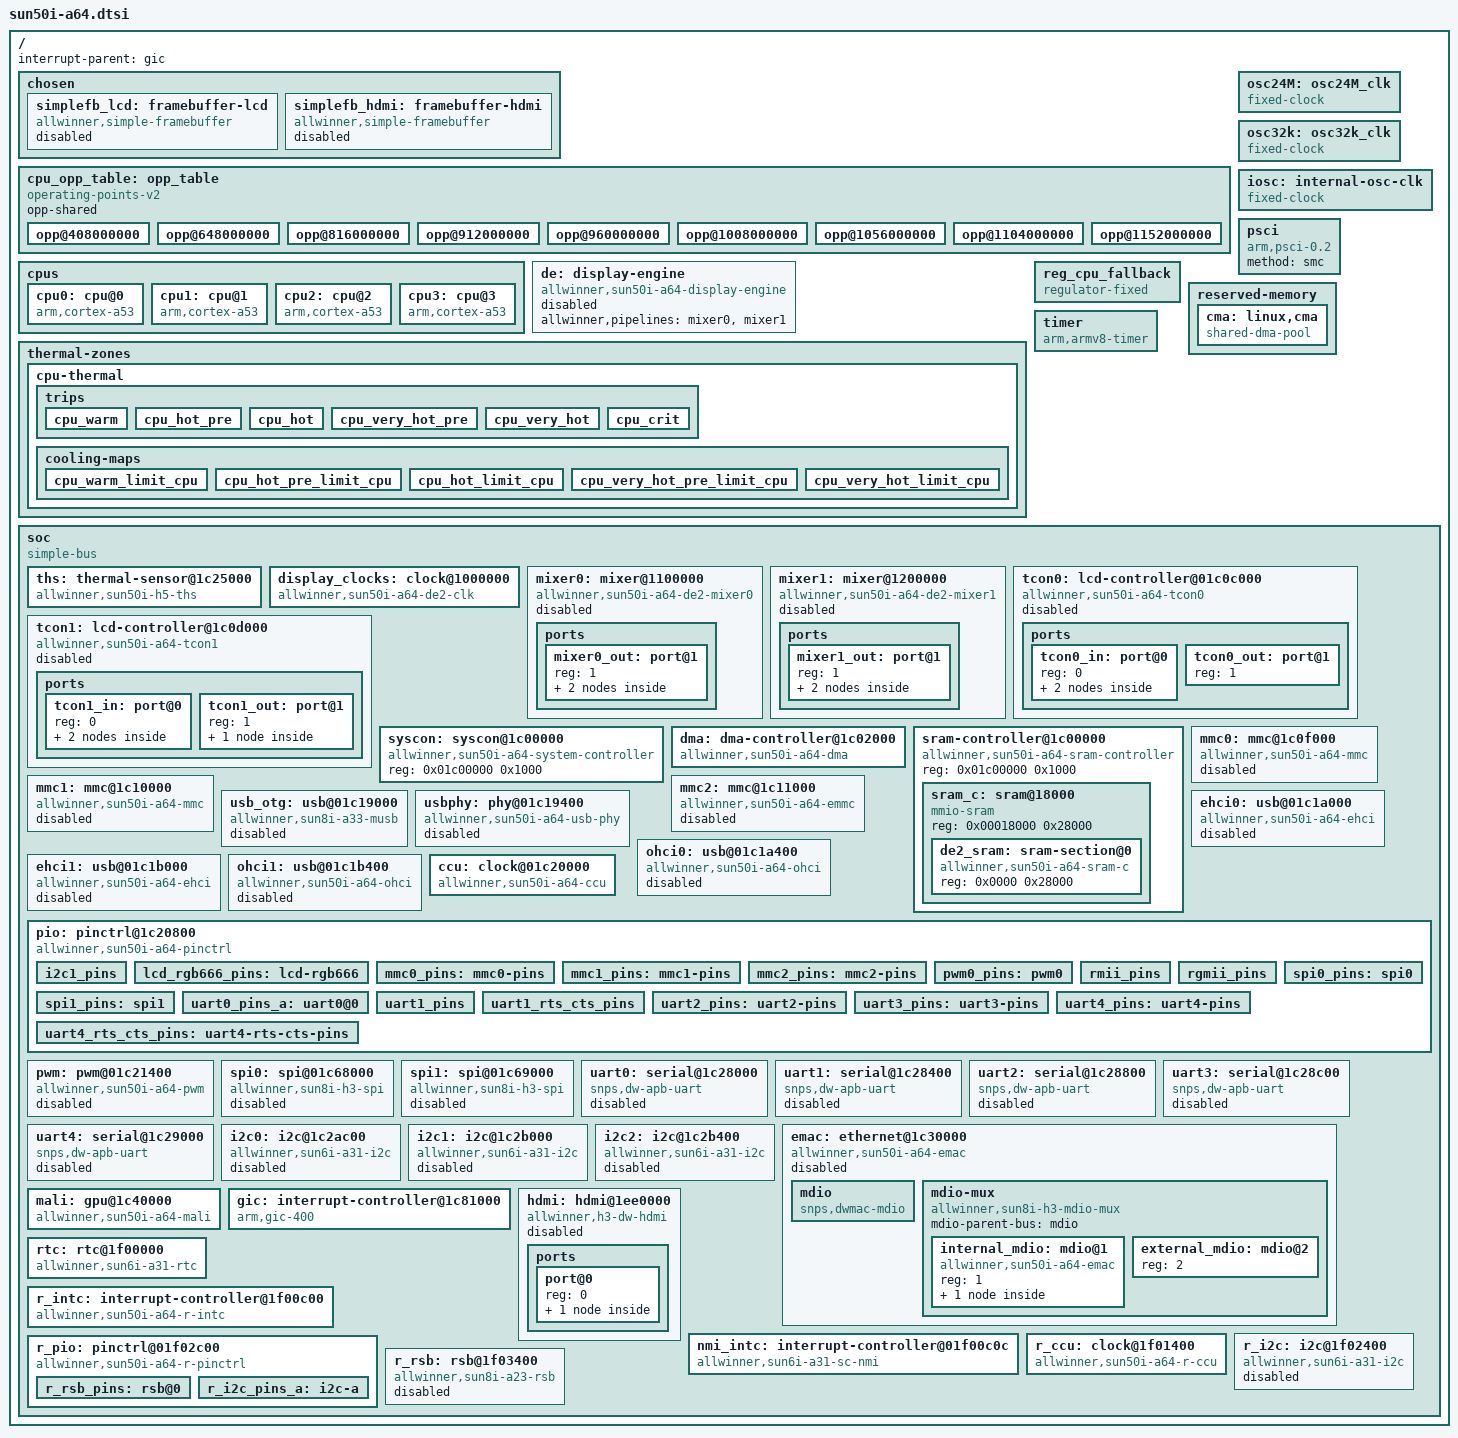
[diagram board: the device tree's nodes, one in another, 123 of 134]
/*
 * Copyright (C) 2016 ARM Ltd.
 * based on the Allwinner H3 dtsi:
 *    Copyright (C) 2015 Jens Kuske <jenskuske@gmail.com>
 *
 * This file is dual-licensed: you can use it either under the terms
 * of the GPL or the X11 license, at your option. Note that this dual
 * licensing only applies to this file, and not this project as a
 * whole.
 *
 *  a) This file is free software; you can redistribute it and/or
 *     modify it under the terms of the GNU General Public License as
 *     published by the Free Software Foundation; either version 2 of the
 *     License, or (at your option) any later version.
 *
 *     This file is distributed in the hope that it will be useful,
 *     but WITHOUT ANY WARRANTY; without even the implied warranty of
 *     MERCHANTABILITY or FITNESS FOR A PARTICULAR PURPOSE.  See the
 *     GNU General Public License for more details.
 *
 * Or, alternatively,
 *
 *  b) Permission is hereby granted, free of charge, to any person
 *     obtaining a copy of this software and associated documentation
 *     files (the "Software"), to deal in the Software without
 *     restriction, including without limitation the rights to use,
 *     copy, modify, merge, publish, distribute, sublicense, and/or
 *     sell copies of the Software, and to permit persons to whom the
 *     Software is furnished to do so, subject to the following
 *     conditions:
 *
 *     The above copyright notice and this permission notice shall be
 *     included in all copies or substantial portions of the Software.
 *
 *     THE SOFTWARE IS PROVIDED "AS IS", WITHOUT WARRANTY OF ANY KIND,
 *     EXPRESS OR IMPLIED, INCLUDING BUT NOT LIMITED TO THE WARRANTIES
 *     OF MERCHANTABILITY, FITNESS FOR A PARTICULAR PURPOSE AND
 *     NONINFRINGEMENT. IN NO EVENT SHALL THE AUTHORS OR COPYRIGHT
 *     HOLDERS BE LIABLE FOR ANY CLAIM, DAMAGES OR OTHER LIABILITY,
 *     WHETHER IN AN ACTION OF CONTRACT, TORT OR OTHERWISE, ARISING
 *     FROM, OUT OF OR IN CONNECTION WITH THE SOFTWARE OR THE USE OR
 *     OTHER DEALINGS IN THE SOFTWARE.
 */

#include <dt-bindings/clock/sun8i-de2.h>
#include <dt-bindings/clock/sun50i-a64-ccu.h>
#include <dt-bindings/clock/sun8i-r-ccu.h>
#include <dt-bindings/interrupt-controller/arm-gic.h>
#include <dt-bindings/reset/sun8i-de2.h>
#include <dt-bindings/reset/sun50i-a64-ccu.h>
#include <dt-bindings/clock/sun8i-de2.h>
#include <dt-bindings/reset/sun8i-de2.h>
#include <dt-bindings/clock/sun8i-r-ccu.h>
#include <dt-bindings/reset/sun8i-r-ccu.h>
#include <dt-bindings/thermal/thermal.h>

/ {
	interrupt-parent = <&gic>;
	#address-cells = <1>;
	#size-cells = <1>;

	chosen {
		#address-cells = <1>;
		#size-cells = <1>;
		ranges;

		simplefb_lcd: framebuffer-lcd {
			compatible = "allwinner,simple-framebuffer",
				     "simple-framebuffer";
			allwinner,pipeline = "mixer0-lcd0";
			clocks = <&display_clocks CLK_BUS_MIXER0>,
				 <&ccu CLK_BUS_TCON0>, <&ccu CLK_BUS_TCON0>,
				 <&display_clocks CLK_MIXER0>,
				 <&ccu CLK_TCON0>;
			status = "disabled";
		};

		simplefb_hdmi: framebuffer-hdmi {
			compatible = "allwinner,simple-framebuffer",
				     "simple-framebuffer";
			allwinner,pipeline = "mixer1-lcd1-hdmi";
			clocks = <&display_clocks CLK_BUS_MIXER1>,
				 <&ccu CLK_BUS_TCON1>, <&ccu CLK_BUS_HDMI>,
				 <&display_clocks CLK_MIXER1>,
				 <&ccu CLK_TCON1>, <&ccu CLK_HDMI>,
				 <&ccu CLK_HDMI_DDC>;
			status = "disabled";
		};
	};

	cpu_opp_table: opp_table {
		compatible = "operating-points-v2";
		opp-shared;

		opp@408000000 {
			opp-hz = /bits/ 64 <408000000>;
			opp-microvolt = <1000000 1000000 1300000>;
			clock-latency-ns = <244144>; /* 8 32k periods */
		};

		opp@648000000 {
			opp-hz = /bits/ 64 <648000000>;
			opp-microvolt = <1040000 1040000 1300000>;
			clock-latency-ns = <244144>; /* 8 32k periods */
		};

		opp@816000000 {
			opp-hz = /bits/ 64 <816000000>;
			opp-microvolt = <1080000 1080000 1300000>;
			clock-latency-ns = <244144>; /* 8 32k periods */
		};

		opp@912000000 {
		       opp-hz = /bits/ 64 <912000000>;
		       opp-microvolt = <1120000 1120000 1300000>;
		       clock-latency-ns = <244144>; /* 8 32k periods */
		};

		opp@960000000 {
		       opp-hz = /bits/ 64 <960000000>;
		       opp-microvolt = <1160000 1160000 1300000>;
		       clock-latency-ns = <244144>; /* 8 32k periods */
		};

		opp@1008000000 {
		       opp-hz = /bits/ 64 <1008000000>;
		       opp-microvolt = <1200000 1200000 1300000>;
		       clock-latency-ns = <244144>; /* 8 32k periods */
		};

		opp@1056000000 {
		       opp-hz = /bits/ 64 <1056000000>;
		       opp-microvolt = <1240000 1240000 1300000>;
		       clock-latency-ns = <244144>; /* 8 32k periods */
		};

		opp@1104000000 {
		       opp-hz = /bits/ 64 <1104000000>;
		       opp-microvolt = <1260000 1260000 1300000>;
		       clock-latency-ns = <244144>; /* 8 32k periods */
		};

		opp@1152000000 {
		       opp-hz = /bits/ 64 <1152000000>;
		       opp-microvolt = <1300000 1300000 1300000>;
		       clock-latency-ns = <244144>; /* 8 32k periods */
		};
	};

	cpus {
		#address-cells = <1>;
		#size-cells = <0>;

		cpu0: cpu@0 {
			compatible = "arm,cortex-a53", "arm,armv8";
			device_type = "cpu";
			reg = <0>;
			enable-method = "psci";
			operating-points-v2 = <&cpu_opp_table>;
			cpu-supply = <&reg_cpu_fallback>;
			#cooling-cells = <2>;
		};

		cpu1: cpu@1 {
			compatible = "arm,cortex-a53", "arm,armv8";
			device_type = "cpu";
			reg = <1>;
			enable-method = "psci";
			operating-points-v2 = <&cpu_opp_table>;
		};

		cpu2: cpu@2 {
			compatible = "arm,cortex-a53", "arm,armv8";
			device_type = "cpu";
			reg = <2>;
			enable-method = "psci";
			operating-points-v2 = <&cpu_opp_table>;
		};

		cpu3: cpu@3 {
			compatible = "arm,cortex-a53", "arm,armv8";
			device_type = "cpu";
			reg = <3>;
			enable-method = "psci";
			operating-points-v2 = <&cpu_opp_table>;
		};
	};

	de: display-engine {
		compatible = "allwinner,sun50i-a64-display-engine";
		allwinner,pipelines = <&mixer0>,
				      <&mixer1>;
		status = "disabled";
	};

	osc24M: osc24M_clk {
		#clock-cells = <0>;
		compatible = "fixed-clock";
		clock-frequency = <24000000>;
		clock-output-names = "osc24M";
	};

	osc32k: osc32k_clk {
		#clock-cells = <0>;
		compatible = "fixed-clock";
		clock-frequency = <32768>;
		clock-output-names = "osc32k";
	};

	iosc: internal-osc-clk {
		#clock-cells = <0>;
		compatible = "fixed-clock";
		clock-frequency = <16000000>;
		clock-accuracy = <300000000>;
		clock-output-names = "iosc";
	};

	psci {
		compatible = "arm,psci-0.2";
		method = "smc";
	};

	thermal-zones {
		cpu-thermal {
			/* milliseconds */
			polling-delay-passive = <250>;
			polling-delay = <1000>;
			thermal-sensors = <&ths>;

			trips {
				cpu_warm: cpu_warm {
					temperature = <65000>;
					hysteresis = <2000>;
					type = "passive";
				};

				cpu_hot_pre: cpu_hot_pre {
					temperature = <70000>;
					hysteresis = <2000>;
					type = "passive";
				};

				cpu_hot: cpu_hot {
					temperature = <75000>;
					hysteresis = <2000>;
					type = "passive";
				};

				cpu_very_hot_pre: cpu_very_hot_pre {
					temperature = <85000>;
					hysteresis = <2000>;
					type = "passive";
				};

				cpu_very_hot: cpu_very_hot {
					temperature = <90000>;
					hysteresis = <2000>;
					type = "passive";
				};

				cpu_crit: cpu_crit {
					temperature = <105000>;
					hysteresis = <2000>;
					type = "critical";
				};
			};

			cooling-maps {
				cpu_warm_limit_cpu {
					trip = <&cpu_warm>;
					cooling-device = <&cpu0 THERMAL_NO_LIMIT 2>;
				};

				cpu_hot_pre_limit_cpu {
					trip = <&cpu_hot_pre>;
					cooling-device = <&cpu0 2 3>;
				};

				cpu_hot_limit_cpu {
					trip = <&cpu_hot>;
					cooling-device = <&cpu0 3 4>;
				};

				cpu_very_hot_pre_limit_cpu {
					trip = <&cpu_very_hot>;
					cooling-device = <&cpu0 5 6>;
				};

				cpu_very_hot_limit_cpu {
					trip = <&cpu_very_hot>;
					cooling-device = <&cpu0 7 THERMAL_NO_LIMIT>;
				};
			};
		};
	};

	reg_cpu_fallback: reg_cpu_fallback  {
		compatible = "regulator-fixed";
		regulator-name = "vdd-cpux-dummy";
		regulator-min-microvolt = <1100000>;
		regulator-max-microvolt = <1100000>;
	};

	reserved-memory {
		#address-cells = <1>;
		#size-cells = <1>;
		ranges;

		cma: linux,cma {
			compatible = "shared-dma-pool";
			reusable;
			size = <0x4000000>;
			alignment = <0x2000>;
			linux,cma-default;
		};
	};
	timer {
		compatible = "arm,armv8-timer";
		fsl,erratum-a008585;
		interrupts = <GIC_PPI 13
			(GIC_CPU_MASK_SIMPLE(4) | IRQ_TYPE_LEVEL_HIGH)>,
			     <GIC_PPI 14
			(GIC_CPU_MASK_SIMPLE(4) | IRQ_TYPE_LEVEL_HIGH)>,
			     <GIC_PPI 11
			(GIC_CPU_MASK_SIMPLE(4) | IRQ_TYPE_LEVEL_HIGH)>,
			     <GIC_PPI 10
			(GIC_CPU_MASK_SIMPLE(4) | IRQ_TYPE_LEVEL_HIGH)>;
	};

	soc {
		compatible = "simple-bus";
		#address-cells = <1>;
		#size-cells = <1>;
		ranges;

		ths: thermal-sensor@1c25000 {
			compatible = "allwinner,sun50i-h5-ths";
			reg = <0x01c25000 0x100>;
			clocks = <&ccu CLK_BUS_THS>, <&ccu CLK_THS>;
			clock-names = "bus", "mod";
			resets = <&ccu RST_BUS_THS>;
			#thermal-sensor-cells = <0>;
			#io-channel-cells = <0>;
		};

		display_clocks: clock@1000000 {
			compatible = "allwinner,sun50i-a64-de2-clk";
			reg = <0x01000000 0x100000>;
			clocks = <&ccu CLK_DE>,
				 <&ccu CLK_BUS_DE>;
			clock-names = "mod",
				      "bus";
			resets = <&ccu RST_BUS_DE>;
			allwinner,sram = <&de2_sram 1>;
			#clock-cells = <1>;
			#reset-cells = <1>;
		};

		mixer0: mixer@1100000 {
			compatible = "allwinner,sun50i-a64-de2-mixer0";
			reg = <0x01100000 0x100000>;
			clocks = <&display_clocks CLK_MIXER0>,
				 <&display_clocks CLK_BUS_MIXER0>;
			clock-names = "mod",
				      "bus";
			resets = <&display_clocks RST_MIXER0>;
			status = "disabled";

			ports {
				#address-cells = <1>;
				#size-cells = <0>;

				mixer0_out: port@1 {
					#address-cells = <1>;
					#size-cells = <0>;
					reg = <1>;

					mixer0_out_tcon0: endpoint@0 {
						reg = <0>;
						remote-endpoint = <&tcon0_in_mixer0>;
					};

					mixer0_out_tcon1: endpoint@1 {
						reg = <1>;
						remote-endpoint = <&tcon1_in_mixer0>;
					};
				};
			};
		};

		mixer1: mixer@1200000 {
			compatible = "allwinner,sun50i-a64-de2-mixer1";
			reg = <0x01200000 0x100000>;
			clocks = <&display_clocks CLK_MIXER1>,
				 <&display_clocks CLK_BUS_MIXER1>;
			clock-names = "mod",
				      "bus";
			resets = <&display_clocks RST_MIXER1>;
			status = "disabled";

			ports {
				#address-cells = <1>;
				#size-cells = <0>;

				mixer1_out: port@1 {
					#address-cells = <1>;
					#size-cells = <0>;
					reg = <1>;

					mixer1_out_tcon1: endpoint@0 {
						reg = <0>;
						remote-endpoint = <&tcon1_in_mixer1>;
					};

					mixer1_out_tcon0: endpoint@1 {
						reg = <1>;
						remote-endpoint = <&tcon0_in_mixer1>;
					};
				};
			};
		};

		tcon0: lcd-controller@01c0c000 {
			compatible = "allwinner,sun50i-a64-tcon0";
			reg = <0x01c0c000 0x1000>;
			interrupts = <GIC_SPI 86 IRQ_TYPE_LEVEL_HIGH>;
			clocks = <&ccu CLK_BUS_TCON0>,
				 <&ccu CLK_TCON0>;
			clock-names = "ahb",
				      "tcon-ch0";
			clock-output-names = "tcon-pixel-clock";
			resets = <&ccu RST_BUS_TCON0>;
			reset-names = "lcd";
			status = "disabled";

			ports {
				#address-cells = <1>;
				#size-cells = <0>;

				tcon0_in: port@0 {
					#address-cells = <1>;
					#size-cells = <0>;
					reg = <0>;

					tcon0_in_mixer0: endpoint@0 {
						reg = <0>;
						remote-endpoint = <&mixer0_out_tcon0>;
					};

					tcon0_in_mixer1: endpoint@1 {
						reg = <1>;
						remote-endpoint = <&mixer1_out_tcon0>;
					};
				};

				tcon0_out: port@1 {
					#address-cells = <1>;
					#size-cells = <0>;
					reg = <1>;
				};
			};
		};

		tcon1: lcd-controller@1c0d000 {
			compatible = "allwinner,sun50i-a64-tcon1";
			reg = <0x01c0d000 0x1000>;
			interrupts = <GIC_SPI 87 IRQ_TYPE_LEVEL_HIGH>;
			clocks = <&ccu CLK_BUS_TCON1>,
				 <&ccu CLK_TCON1>;
			clock-names = "ahb",
				      "tcon-ch1";
			resets = <&ccu RST_BUS_TCON1>;
			reset-names = "lcd";
			status = "disabled";

			ports {
				#address-cells = <1>;
				#size-cells = <0>;

				tcon1_in: port@0 {
					#address-cells = <1>;
					#size-cells = <0>;
					reg = <0>;

					tcon1_in_mixer1: endpoint@0 {
						reg = <0>;
						remote-endpoint = <&mixer1_out_tcon1>;
					};

					tcon1_in_mixer0: endpoint@1 {
						reg = <1>;
						remote-endpoint = <&mixer0_out_tcon1>;
					};
				};

				tcon1_out: port@1 {
					#address-cells = <1>;
					#size-cells = <0>;
					reg = <1>;

					tcon1_out_hdmi: endpoint@1 {
						reg = <1>;
						remote-endpoint = <&hdmi_in_tcon1>;
					};
				};
			};
		};

		syscon: syscon@1c00000 {
			compatible = "allwinner,sun50i-a64-system-controller",
				"syscon";
			reg = <0x01c00000 0x1000>;
		};

		dma: dma-controller@1c02000 {
			compatible = "allwinner,sun50i-a64-dma";
			reg = <0x01c02000 0x1000>;
			interrupts = <GIC_SPI 50 IRQ_TYPE_LEVEL_HIGH>;
			clocks = <&ccu CLK_BUS_DMA>;
			dma-channels = <8>;
			dma-requests = <27>;
			resets = <&ccu RST_BUS_DMA>;
			#dma-cells = <1>;
		};

		sram-controller@1c00000 {
			compatible = "allwinner,sun50i-a64-sram-controller";
			reg = <0x01c00000 0x1000>;
			#address-cells = <1>;
			#size-cells = <1>;
			ranges;

			sram_c: sram@18000 {
				compatible = "mmio-sram";
				reg = <0x00018000 0x28000>;
				#address-cells = <1>;
				#size-cells = <1>;
				ranges = <0 0x00018000 0x28000>;

				de2_sram: sram-section@0 {
					compatible = "allwinner,sun50i-a64-sram-c";
					reg = <0x0000 0x28000>;
				};
			};
		};

		mmc0: mmc@1c0f000 {
			compatible = "allwinner,sun50i-a64-mmc";
			reg = <0x01c0f000 0x1000>;
			clocks = <&ccu CLK_BUS_MMC0>, <&ccu CLK_MMC0>;
			clock-names = "ahb", "mmc";
			resets = <&ccu RST_BUS_MMC0>;
			reset-names = "ahb";
			interrupts = <GIC_SPI 60 IRQ_TYPE_LEVEL_HIGH>;
			max-frequency = <150000000>;
			status = "disabled";
			#address-cells = <1>;
			#size-cells = <0>;
		};

		mmc1: mmc@1c10000 {
			compatible = "allwinner,sun50i-a64-mmc";
			reg = <0x01c10000 0x1000>;
			clocks = <&ccu CLK_BUS_MMC1>, <&ccu CLK_MMC1>;
			clock-names = "ahb", "mmc";
			resets = <&ccu RST_BUS_MMC1>;
			reset-names = "ahb";
			interrupts = <GIC_SPI 61 IRQ_TYPE_LEVEL_HIGH>;
			max-frequency = <150000000>;
			status = "disabled";
			#address-cells = <1>;
			#size-cells = <0>;
		};

		mmc2: mmc@1c11000 {
			compatible = "allwinner,sun50i-a64-emmc";
			reg = <0x01c11000 0x1000>;
			clocks = <&ccu CLK_BUS_MMC2>, <&ccu CLK_MMC2>;
			clock-names = "ahb", "mmc";
			resets = <&ccu RST_BUS_MMC2>;
			reset-names = "ahb";
			interrupts = <GIC_SPI 62 IRQ_TYPE_LEVEL_HIGH>;
			max-frequency = <200000000>;
			status = "disabled";
			#address-cells = <1>;
			#size-cells = <0>;
		};

		usb_otg: usb@01c19000 {
			compatible = "allwinner,sun8i-a33-musb";
			reg = <0x01c19000 0x0400>;
			clocks = <&ccu CLK_BUS_OTG>;
			resets = <&ccu RST_BUS_OTG>;
			interrupts = <GIC_SPI 71 IRQ_TYPE_LEVEL_HIGH>;
			interrupt-names = "mc";
			phys = <&usbphy 0>;
			phy-names = "usb";
			extcon = <&usbphy 0>;
			status = "disabled";
		};

		usbphy: phy@01c19400 {
			compatible = "allwinner,sun50i-a64-usb-phy";
			reg = <0x01c19400 0x14>,
			      <0x01c1a800 0x4>,
			      <0x01c1b800 0x4>;
			reg-names = "phy_ctrl",
				    "pmu0",
				    "pmu1";
			clocks = <&ccu CLK_USB_PHY0>,
				 <&ccu CLK_USB_PHY1>;
			clock-names = "usb0_phy",
				      "usb1_phy";
			resets = <&ccu RST_USB_PHY0>,
				 <&ccu RST_USB_PHY1>;
			reset-names = "usb0_reset",
				      "usb1_reset";
			status = "disabled";
			#phy-cells = <1>;
		};

		ehci0: usb@01c1a000 {
			compatible = "allwinner,sun50i-a64-ehci", "generic-ehci";
			reg = <0x01c1a000 0x100>;
			interrupts = <GIC_SPI 72 IRQ_TYPE_LEVEL_HIGH>;
			clocks = <&ccu CLK_BUS_OHCI0>,
				 <&ccu CLK_BUS_EHCI0>,
				 <&ccu CLK_USB_OHCI0>;
			resets = <&ccu RST_BUS_OHCI0>,
				 <&ccu RST_BUS_EHCI0>;
			status = "disabled";
		};

		ohci0: usb@01c1a400 {
			compatible = "allwinner,sun50i-a64-ohci", "generic-ohci";
			reg = <0x01c1a400 0x100>;
			interrupts = <GIC_SPI 73 IRQ_TYPE_LEVEL_HIGH>;
			clocks = <&ccu CLK_BUS_OHCI0>,
				 <&ccu CLK_USB_OHCI0>;
			resets = <&ccu RST_BUS_OHCI0>;
			status = "disabled";
		};

		ehci1: usb@01c1b000 {
			compatible = "allwinner,sun50i-a64-ehci", "generic-ehci";
			reg = <0x01c1b000 0x100>;
			interrupts = <GIC_SPI 74 IRQ_TYPE_LEVEL_HIGH>;
			clocks = <&ccu CLK_BUS_OHCI1>,
				 <&ccu CLK_BUS_EHCI1>,
				 <&ccu CLK_USB_OHCI1>;
			resets = <&ccu RST_BUS_OHCI1>,
				 <&ccu RST_BUS_EHCI1>;
			phys = <&usbphy 1>;
			phy-names = "usb";
			status = "disabled";
		};

		ohci1: usb@01c1b400 {
			compatible = "allwinner,sun50i-a64-ohci", "generic-ohci";
			reg = <0x01c1b400 0x100>;
			interrupts = <GIC_SPI 75 IRQ_TYPE_LEVEL_HIGH>;
			clocks = <&ccu CLK_BUS_OHCI1>,
				 <&ccu CLK_USB_OHCI1>;
			resets = <&ccu RST_BUS_OHCI1>;
			phys = <&usbphy 1>;
			phy-names = "usb";
			status = "disabled";
		};

		ccu: clock@01c20000 {
			compatible = "allwinner,sun50i-a64-ccu";
			reg = <0x01c20000 0x400>;
			clocks = <&osc24M>, <&osc32k>;
			clock-names = "hosc", "losc";
			#clock-cells = <1>;
			#reset-cells = <1>;
		};

		pio: pinctrl@1c20800 {
			compatible = "allwinner,sun50i-a64-pinctrl";
			reg = <0x01c20800 0x400>;
			interrupts = <GIC_SPI 11 IRQ_TYPE_LEVEL_HIGH>,
				     <GIC_SPI 17 IRQ_TYPE_LEVEL_HIGH>,
				     <GIC_SPI 21 IRQ_TYPE_LEVEL_HIGH>;
			clocks = <&ccu 58>;
			gpio-controller;
			#gpio-cells = <3>;
			interrupt-controller;
			#interrupt-cells = <3>;

			i2c1_pins: i2c1_pins {
				pins = "PH2", "PH3";
				function = "i2c1";
			};

			lcd_rgb666_pins: lcd-rgb666 {
				pins = "PD0", "PD1", "PD2", "PD3", "PD4",
				       "PD5", "PD6", "PD7", "PD8", "PD9",
				       "PD10", "PD11", "PD12", "PD13",
				       "PD14", "PD15", "PD16", "PD17",
				       "PD18", "PD19", "PD20", "PD21";
				function = "lcd0";
			};

			mmc0_pins: mmc0-pins {
				pins = "PF0", "PF1", "PF2", "PF3",
				       "PF4", "PF5";
				function = "mmc0";
				drive-strength = <30>;
				bias-pull-up;
			};

			mmc1_pins: mmc1-pins {
				pins = "PG0", "PG1", "PG2", "PG3",
				       "PG4", "PG5";
				function = "mmc1";
				drive-strength = <30>;
				bias-pull-up;
			};

			mmc2_pins: mmc2-pins {
				pins = "PC1", "PC5", "PC6", "PC8", "PC9",
				       "PC10","PC11", "PC12", "PC13",
				       "PC14", "PC15", "PC16";
				function = "mmc2";
				drive-strength = <30>;
				bias-pull-up;
			};

			pwm0_pins: pwm0 {
				pins = "PD22";
				function = "pwm";
			};

			rmii_pins: rmii_pins {
				pins = "PD10", "PD11", "PD13", "PD14", "PD17",
				       "PD18", "PD19", "PD20", "PD22", "PD23";
				function = "emac";
				drive-strength = <40>;
			};

			rgmii_pins: rgmii_pins {
				pins = "PD8", "PD9", "PD10", "PD11", "PD12",
				       "PD13", "PD15", "PD16", "PD17", "PD18",
				       "PD19", "PD20", "PD21", "PD22", "PD23";
				function = "emac";
				drive-strength = <40>;
			};

			spi0_pins: spi0 {
				pins = "PC0", "PC1", "PC2", "PC3";
				function = "spi0";
			};

			spi1_pins: spi1 {
				pins = "PA15", "PA16", "PA14", "PA13";
				function = "spi1";
			};

			uart0_pins_a: uart0@0 {
				pins = "PB8", "PB9";
				function = "uart0";
			};

			uart1_pins: uart1_pins {
				pins = "PG6", "PG7";
				function = "uart1";
			};

			uart1_rts_cts_pins: uart1_rts_cts_pins {
				pins = "PG8", "PG9";
				function = "uart1";
			};

			uart2_pins: uart2-pins {
				pins = "PB0", "PB1";
				function = "uart2";
			};

			uart3_pins: uart3-pins {
				pins = "PD0", "PD1";
				function = "uart3";
			};

			uart4_pins: uart4-pins {
				pins = "PD2", "PD3";
				function = "uart4";
			};

			uart4_rts_cts_pins: uart4-rts-cts-pins {
				pins = "PD4", "PD5";
				function = "uart4";
			};
		};

		pwm: pwm@01c21400 {
			compatible = "allwinner,sun50i-a64-pwm";
			reg = <0x01c21400 0x8>;
			clocks = <&osc24M>;
			#pwm-cells = <3>;
			status = "disabled";
		};

		spi0: spi@01c68000 {
			compatible = "allwinner,sun8i-h3-spi";
			reg = <0x01c68000 0x1000>;
			interrupts = <GIC_SPI 65 IRQ_TYPE_LEVEL_HIGH>;
			clocks = <&ccu CLK_BUS_SPI0>, <&ccu CLK_SPI0>;
			clock-names = "ahb", "mod";
			pinctrl-names = "default";
			pinctrl-0 = <&spi0_pins>;
			resets = <&ccu RST_BUS_SPI0>;
			status = "disabled";
			#address-cells = <1>;
			#size-cells = <0>;
		};

		spi1: spi@01c69000 {
			compatible = "allwinner,sun8i-h3-spi";
			reg = <0x01c69000 0x1000>;
			interrupts = <GIC_SPI 66 IRQ_TYPE_LEVEL_HIGH>;
			clocks = <&ccu CLK_BUS_SPI1>, <&ccu CLK_SPI1>;
			clock-names = "ahb", "mod";
			pinctrl-names = "default";
			pinctrl-0 = <&spi1_pins>;
			resets = <&ccu RST_BUS_SPI1>;
			status = "disabled";
			#address-cells = <1>;
			#size-cells = <0>;
		};

		uart0: serial@1c28000 {
			compatible = "snps,dw-apb-uart";
			reg = <0x01c28000 0x400>;
			interrupts = <GIC_SPI 0 IRQ_TYPE_LEVEL_HIGH>;
			reg-shift = <2>;
			reg-io-width = <4>;
			clocks = <&ccu CLK_BUS_UART0>;
			resets = <&ccu RST_BUS_UART0>;
			status = "disabled";
		};

		uart1: serial@1c28400 {
			compatible = "snps,dw-apb-uart";
			reg = <0x01c28400 0x400>;
			interrupts = <GIC_SPI 1 IRQ_TYPE_LEVEL_HIGH>;
			reg-shift = <2>;
			reg-io-width = <4>;
			clocks = <&ccu CLK_BUS_UART1>;
			resets = <&ccu RST_BUS_UART1>;
			status = "disabled";
		};

		uart2: serial@1c28800 {
			compatible = "snps,dw-apb-uart";
			reg = <0x01c28800 0x400>;
			interrupts = <GIC_SPI 2 IRQ_TYPE_LEVEL_HIGH>;
			reg-shift = <2>;
			reg-io-width = <4>;
			clocks = <&ccu CLK_BUS_UART2>;
			resets = <&ccu RST_BUS_UART2>;
			status = "disabled";
		};

		uart3: serial@1c28c00 {
			compatible = "snps,dw-apb-uart";
			reg = <0x01c28c00 0x400>;
			interrupts = <GIC_SPI 3 IRQ_TYPE_LEVEL_HIGH>;
			reg-shift = <2>;
			reg-io-width = <4>;
			clocks = <&ccu CLK_BUS_UART3>;
			resets = <&ccu RST_BUS_UART3>;
			status = "disabled";
		};

		uart4: serial@1c29000 {
			compatible = "snps,dw-apb-uart";
			reg = <0x01c29000 0x400>;
			interrupts = <GIC_SPI 4 IRQ_TYPE_LEVEL_HIGH>;
			reg-shift = <2>;
			reg-io-width = <4>;
			clocks = <&ccu CLK_BUS_UART4>;
			resets = <&ccu RST_BUS_UART4>;
			status = "disabled";
		};

		i2c0: i2c@1c2ac00 {
			compatible = "allwinner,sun6i-a31-i2c";
			reg = <0x01c2ac00 0x400>;
			interrupts = <GIC_SPI 6 IRQ_TYPE_LEVEL_HIGH>;
			clocks = <&ccu CLK_BUS_I2C0>;
			resets = <&ccu RST_BUS_I2C0>;
			status = "disabled";
			#address-cells = <1>;
			#size-cells = <0>;
		};

		i2c1: i2c@1c2b000 {
			compatible = "allwinner,sun6i-a31-i2c";
			reg = <0x01c2b000 0x400>;
			interrupts = <GIC_SPI 7 IRQ_TYPE_LEVEL_HIGH>;
			clocks = <&ccu CLK_BUS_I2C1>;
			resets = <&ccu RST_BUS_I2C1>;
			status = "disabled";
			#address-cells = <1>;
			#size-cells = <0>;
		};

		i2c2: i2c@1c2b400 {
			compatible = "allwinner,sun6i-a31-i2c";
			reg = <0x01c2b400 0x400>;
			interrupts = <GIC_SPI 8 IRQ_TYPE_LEVEL_HIGH>;
			clocks = <&ccu CLK_BUS_I2C2>;
			resets = <&ccu RST_BUS_I2C2>;
			status = "disabled";
			#address-cells = <1>;
			#size-cells = <0>;
		};

		emac: ethernet@1c30000 {
			compatible = "allwinner,sun50i-a64-emac";
			syscon = <&syscon>;
			reg = <0x01c30000 0x10000>;
			interrupts = <GIC_SPI 82 IRQ_TYPE_LEVEL_HIGH>;
			interrupt-names = "macirq";
			resets = <&ccu RST_BUS_EMAC>;
			reset-names = "stmmaceth";
			clocks = <&ccu CLK_BUS_EMAC>;
			clock-names = "stmmaceth";
			status = "disabled";
			#address-cells = <1>;
			#size-cells = <0>;

			mdio: mdio {
				#address-cells = <1>;
				#size-cells = <0>;
				compatible = "snps,dwmac-mdio";
			};

			mdio-mux {
				compatible = "allwinner,sun8i-h3-mdio-mux";
				#address-cells = <1>;
				#size-cells = <0>;

				mdio-parent-bus = <&mdio>;
				/* Only one MDIO is usable at the time */
				internal_mdio: mdio@1 {
					compatible = "allwinner,sun50i-a64-emac";
 					reg = <1>;
					#address-cells = <1>;
					#size-cells = <0>;

					int_mii_phy: ethernet-phy@1 {
						compatible = "ethernet-phy-ieee802.3-c22";
						reg = <1>;
						clocks = <&ccu CLK_BUS_EMAC>;
						resets = <&ccu RST_BUS_EMAC>;
					};
				};

				external_mdio: mdio@2 {
					reg = <2>;
					#address-cells = <1>;
					#size-cells = <0>;
 				};
 			};
		};

		mali: gpu@1c40000 {
			compatible = "allwinner,sun50i-a64-mali",
				     "allwinner,sun7i-a20-mali", "arm,mali-400";
			reg = <0x01c40000 0x10000>;
			interrupts = <GIC_SPI 97 IRQ_TYPE_LEVEL_HIGH>,
				     <GIC_SPI 98 IRQ_TYPE_LEVEL_HIGH>,
				     <GIC_SPI 99 IRQ_TYPE_LEVEL_HIGH>,
				     <GIC_SPI 100 IRQ_TYPE_LEVEL_HIGH>,
				     <GIC_SPI 102 IRQ_TYPE_LEVEL_HIGH>,
				     <GIC_SPI 103 IRQ_TYPE_LEVEL_HIGH>,
				     <GIC_SPI 101 IRQ_TYPE_LEVEL_HIGH>;
			interrupt-names = "gp",
					  "gpmmu",
					  "pp0",
					  "ppmmu0",
					  "pp1",
					  "ppmmu1",
					  "pmu";
			clocks = <&ccu CLK_BUS_GPU>, <&ccu CLK_GPU>;
			clock-names = "bus", "core";
			resets = <&ccu RST_BUS_GPU>;
			memory-region = <&cma>;

			assigned-clocks = <&ccu CLK_GPU>;
			assigned-clock-rates = <384000000>;
		};

		gic: interrupt-controller@1c81000 {
			compatible = "arm,gic-400";
			reg = <0x01c81000 0x1000>,
			      <0x01c82000 0x2000>,
			      <0x01c84000 0x2000>,
			      <0x01c86000 0x2000>;
			interrupts = <GIC_PPI 9 (GIC_CPU_MASK_SIMPLE(4) | IRQ_TYPE_LEVEL_HIGH)>;
			interrupt-controller;
			#interrupt-cells = <3>;
		};

		hdmi: hdmi@1ee0000 {
			compatible = "allwinner,h3-dw-hdmi";
			reg = <0x01ee0000 0x10000>,
			      <0x01ef0000 0x10000>;
			reg-io-width = <1>;
			interrupts = <GIC_SPI 88 IRQ_TYPE_LEVEL_HIGH>;
			clocks = <&ccu CLK_BUS_HDMI>, <&ccu CLK_HDMI>,
				 <&ccu CLK_HDMI_DDC>;
			clock-names = "iahb", "isfr", "iddc";
			resets = <&ccu RST_BUS_HDMI0>, <&ccu RST_BUS_HDMI1>;
			reset-names = "hdmi", "ddc";
			status = "disabled";

			ports {
				#address-cells = <1>;
				#size-cells = <0>;

				port@0 {
					reg = <0>;
					#address-cells = <1>;
					#size-cells = <0>;

					hdmi_in_tcon1: endpoint@0 {
						reg = <0>;
						remote-endpoint = <&tcon1_out_hdmi>;
					};
				};
			};
		};

		rtc: rtc@1f00000 {
			compatible = "allwinner,sun6i-a31-rtc";
			reg = <0x01f00000 0x54>;
			interrupts = <GIC_SPI 40 IRQ_TYPE_LEVEL_HIGH>,
				     <GIC_SPI 41 IRQ_TYPE_LEVEL_HIGH>;
		};

		r_intc: interrupt-controller@1f00c00 {
			compatible = "allwinner,sun50i-a64-r-intc",
				     "allwinner,sun6i-a31-r-intc";
			interrupt-controller;
			#interrupt-cells = <2>;
			reg = <0x01f00c00 0x400>;
			interrupts = <GIC_SPI 32 IRQ_TYPE_LEVEL_HIGH>;
		};

		nmi_intc: interrupt-controller@01f00c0c {
			compatible = "allwinner,sun6i-a31-sc-nmi";
			interrupt-controller;
			#interrupt-cells = <2>;
			reg = <0x01f00c0c 0x38>;
			interrupts = <GIC_SPI 32 IRQ_TYPE_LEVEL_HIGH>;
		};

		r_ccu: clock@1f01400 {
			compatible = "allwinner,sun50i-a64-r-ccu";
			reg = <0x01f01400 0x100>;
			clocks = <&osc24M>, <&osc32k>, <&iosc>,
				 <&ccu 11>;
			clock-names = "hosc", "losc", "iosc", "pll-periph";
			#clock-cells = <1>;
			#reset-cells = <1>;
		};

		r_i2c: i2c@1f02400 {
			compatible = "allwinner,sun6i-a31-i2c";
			reg = <0x01f02400 0x400>;
			interrupts = <GIC_SPI 44 IRQ_TYPE_LEVEL_HIGH>;
			clocks = <&r_ccu CLK_APB0_I2C>;
			resets = <&r_ccu RST_APB0_I2C>;
			status = "disabled";
			#address-cells = <1>;
			#size-cells = <0>;
		};

		r_pio: pinctrl@01f02c00 {
			compatible = "allwinner,sun50i-a64-r-pinctrl";
			reg = <0x01f02c00 0x400>;
			interrupts = <GIC_SPI 45 IRQ_TYPE_LEVEL_HIGH>;
			clocks = <&r_ccu CLK_APB0_PIO>, <&osc24M>, <&osc32k>;
			clock-names = "apb", "hosc", "losc";
			gpio-controller;
			#gpio-cells = <3>;
			interrupt-controller;
			#interrupt-cells = <3>;

			r_rsb_pins: rsb@0 {
				pins = "PL0", "PL1";
				function = "s_rsb";
			};

			r_i2c_pins_a: i2c-a {
				pins = "PL8", "PL9";
				function = "s_i2c";
			};
		};

		r_rsb: rsb@1f03400 {
			compatible = "allwinner,sun8i-a23-rsb";
			reg = <0x01f03400 0x400>;
			interrupts = <GIC_SPI 39 IRQ_TYPE_LEVEL_HIGH>;
			clocks = <&r_ccu 6>;
			clock-frequency = <3000000>;
			resets = <&r_ccu 2>;
			pinctrl-names = "default";
			pinctrl-0 = <&r_rsb_pins>;
			status = "disabled";
			#address-cells = <1>;
			#size-cells = <0>;
		};
	};
};
